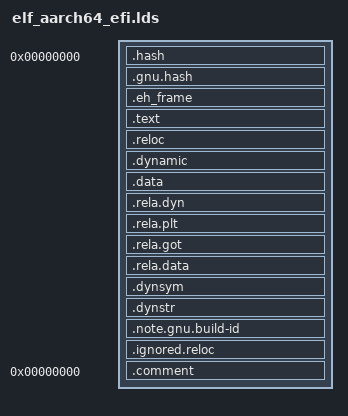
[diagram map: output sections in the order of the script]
OUTPUT_FORMAT("elf64-littleaarch64", "elf64-littleaarch64", "elf64-littleaarch64")
OUTPUT_ARCH(aarch64)
ENTRY(_start)
SECTIONS
{
  . = 0;
  ImageBase = .;
  /* .hash and/or .gnu.hash MUST come first! */
  .hash : { *(.hash) }
  .gnu.hash : { *(.gnu.hash) }
  . = ALIGN(4096);
  .eh_frame : 
  { 
    *(.eh_frame)
  }
  .text : {
    _text = .;
    *(.text)
    *(.text.*)
    *(.gnu.linkonce.t.*)
    *(.srodata)
    *(.rodata*)
    . = ALIGN(16);
  }
  _etext = .;
  _text_size = . - _text;
  . = ALIGN(4096);
  .reloc :
  {
   *(.reloc)
  }
  . = DATA_SEGMENT_ALIGN (CONSTANT (MAXPAGESIZE), CONSTANT (COMMONPAGESIZE));
  .dynamic  : { *(.dynamic) }
  .data :
  {
   _data = .;
   *(.sdata)
   *(.data)
   *(.data1)
   *(.data.*)
   *(.got.plt)
   *(.got)

   /* the EFI loader doesn't seem to like a .bss section, so we stick
      it all into .data: */
   . = ALIGN(16);
   _bss = .;
   *(.sbss)
   *(.scommon)
   *(.dynbss)
   *(.bss)
   *(COMMON)
   *(.rel.local)
   . = ALIGN(16);
   _bss_end = .;
  }

  .rela.dyn : { *(.rela.dyn) }
  .rela.plt : { *(.rela.plt) }
  .rela.got : { *(.rela.got) }
  .rela.data : { *(.rela.data) *(.rela.data*) }
  . = ALIGN(512);
  _edata = .;
  _data_size = . - _data;

  . = ALIGN(4096);
  .dynsym   : { *(.dynsym) }
  . = ALIGN(4096);
  .dynstr   : { *(.dynstr) }
  . = ALIGN(4096);
  .note.gnu.build-id : { *(.note.gnu.build-id) }
  . = DATA_SEGMENT_END (.);
  .ignored.reloc :
  {
    *(.rela.reloc)
    *(.eh_frame)
    *(.note.GNU-stack)
  }
  .comment 0 : { *(.comment) }
}
